# ATmega406 register map
Vendor: Atmel; File version: 1.0
CPU: other r0p0, little endian, no MPU, no FPU, 4 interrupt priority bits
Registers are 8-bit, read-write, reset 0x0 unless marked. A register's access mark holds for its fields unless they carry their own. Offsets are from the block's base; [hi:lo] are bit positions; {n}, {i} and the like mark numbered series.

## BOOT_LOAD — Bootloader
Base 0x00800057
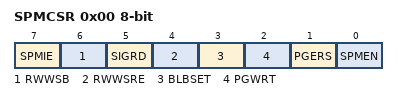
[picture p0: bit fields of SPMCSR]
0x00 SPMCSR — Store Program Memory Control Register
  [7] SPMIE — SPM Interrupt Enable
  [6] RWWSB — Read While Write Section Busy
  [5] SIGRD — Signature Row Read
  [4] RWWSRE — Read While Write section read enable
  [3] BLBSET — Boot Lock Bit Set
  [2] PGWRT — Page Write
  [1] PGERS — Page Erase
  [0] SPMEN — Store Program Memory Enable

## CELL_BALANCING
Base 0x008000F1
0x00 CBCR — Cell Balancing Control Register
  [3:0] CBE — Cell Balancing Enables

## COULOMB_COUNTER
Base 0x008000E0
{0x0+i} CADAC{i} (i=0..3) — ADC Accumulate Current (read-only for debugger)
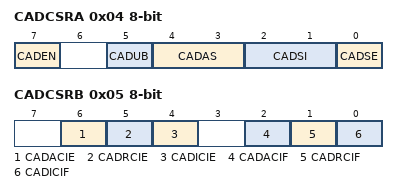
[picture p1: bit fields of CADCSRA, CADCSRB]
0x04 CADCSRA — CC-ADC Control and Status Register A
  [7] CADEN — When the CADEN bit is cleared (zero), the CC-ADC is disabled. When the CADEN bit is set (one), the CC-ADC will continuously measure the voltage drop over the external sense resistor RSENSE. In Power-down, only the Regular Current detection is active. In Power-off, the CC-ADC is always disabled.
  [5] CADUB — CC_ADC Update Busy
  [4:3] CADAS — CC_ADC Accumulate Current Select Bits
    0=125MS; 1=250MS; 2=500MS; 3=1000MS
  [2:1] CADSI — The CADSI bits determine the current sampling interval for the Regular Current detection in Power-down mode. The actual settings remain to be determined.
    0=125MS; 1=250MS; 2=500MS; 3=1000MS
  [0] CADSE — When the CADSE bit is written to one, the ongoing CC-ADC conversion is aborted, and the CC-ADC enters Regular Current detection mode.
0x05 CADCSRB — CC-ADC Control and Status Register B (read-only for debugger)
  [6] CADACIE
  [5] CADRCIE — Regular Current Interrupt Enable
  [4] CADICIE — CAD Instantaneous Current Interrupt Enable
  [2] CADACIF — CC-ADC Accumulate Current Interrupt Flag
  [1] CADRCIF — CC-ADC Accumulate Current Interrupt Flag
  [0] CADICIF — CC-ADC Instantaneous Current Interrupt Flag
0x06 CADRCC — CC-ADC Regular Charge Current
0x07 CADRDC — CC-ADC Regular Discharge Current
0x08 CADIC 16-bit (reset mask 0xFF) — CC-ADC Instantaneous Current

## CPU — CPU Registers
Base 0x0080003E
0x00 GPIOR0 — General Purpose IO Register 0
0x0C GPIOR1 — General Purpose IO Register 1
0x0D GPIOR2 — General Purpose IO Register 2
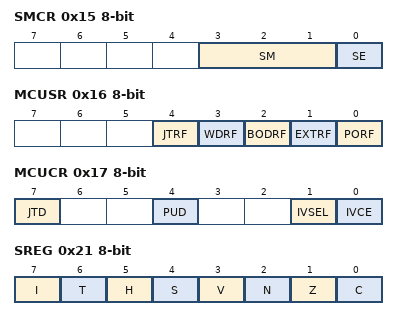
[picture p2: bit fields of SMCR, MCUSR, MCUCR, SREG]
0x15 SMCR — Sleep Mode Control Register
  [3:1] SM — Sleep Mode Select bits
    0=IDLE; 1=ADC (ADC Noise Reduction (If Available)); 2=PDOWN (Power Down); 3=PSAVE (Power Save); 4=POFF (Power Off)
  [0] SE — Sleep Enable
0x16 MCUSR — MCU Status Register
  [4] JTRF — JTAG Reset Flag
  [3] WDRF — Watchdog Reset Flag
  [2] BODRF — Brown-out Reset Flag
  [1] EXTRF — External Reset Flag
  [0] PORF — Power-on reset flag
0x17 MCUCR — MCU Control Register
  [7] JTD — JTAG Disable
  [4] PUD — Pull-up disable
  [1] IVSEL — Interrupt Vector Select
  [0] IVCE — Interrupt Vector Change Enable
0x1F SP 16-bit (reset mask 0xFF) — Stack Pointer
0x21 SREG — Status Register
  [7] I — Global Interrupt Enable
  [6] T — Bit Copy Storage
  [5] H — Half Carry Flag
  [4] S — Sign Bit
  [3] V — Two's Complement Overflow Flag
  [2] N — Negative Flag
  [1] Z — Zero Flag
  [0] C — Carry Flag
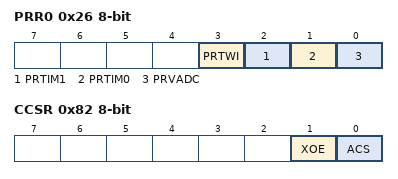
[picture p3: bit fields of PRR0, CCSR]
0x26 PRR0 — Power Reduction Register 0
  [3] PRTWI — Power Reduction TWI
  [2] PRTIM1 — Power Reduction Timer/Counter1
  [1] PRTIM0 — Power Reduction Timer/Counter0
  [0] PRVADC — Power Reduction V-ADC
0x28 FOSCCAL — Fast Oscillator Calibration Value
0x40 DIDR0 — Digital Input Disable Register
0x82 CCSR — Clock Control and Status Register
  [1] XOE — 32 kHz Crystal Oscillator Enable
  [0] ACS — Asynchronous Clock Select

## EEPROM
Base 0x0080003F
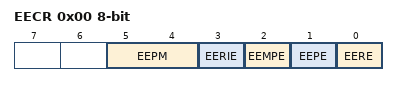
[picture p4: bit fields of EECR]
0x00 EECR — EEPROM Control Register
  [5:4] EEPM — EEPROM Programming Mode Bits
    0=ERASE_AND_WRITE_IN_ONE_OPERATION; 1=ERASE_ONLY; 2=WRITE_ONLY
  [3] EERIE — EEPROM Ready Interrupt Enable
  [2] EEMPE — EEPROM Master Programming Enable
  [1] EEPE — EEPROM Programming Enable
  [0] EERE — EEPROM Read Enable
0x01 EEDR — EEPROM Data Register
0x02 EEAR 16-bit (reset mask 0xFF) — EEPROM Address Register Bytes
